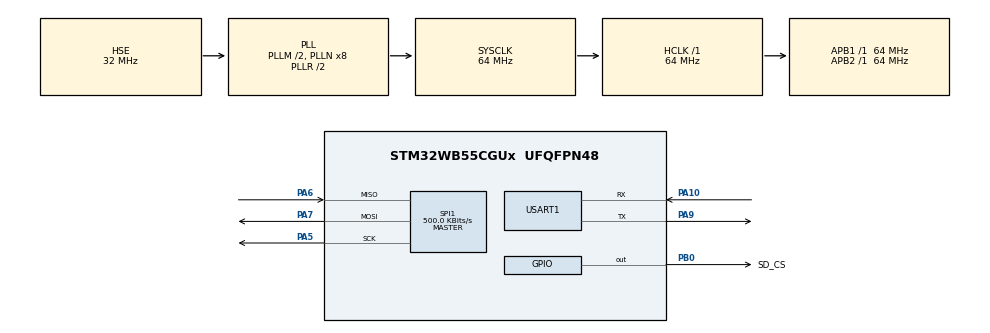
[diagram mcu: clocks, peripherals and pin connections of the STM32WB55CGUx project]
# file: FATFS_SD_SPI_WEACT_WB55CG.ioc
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Mcu.Family=STM32WB
Mcu.Name=STM32WB55CGUx
Mcu.Package=UFQFPN48
NVIC.PriorityGroup=NVIC_PRIORITYGROUP_4
OSC_IN.Mode=HSE-External-Oscillator
OSC_IN.Signal=RCC_OSC_IN
OSC_OUT.Mode=HSE-External-Oscillator
OSC_OUT.Signal=RCC_OSC_OUT
PA10.Mode=Asynchronous
PA10.Signal=USART1_RX
PA5.Mode=Full_Duplex_Master
PA5.Signal=SPI1_SCK
PA6.Mode=Full_Duplex_Master
PA6.Signal=SPI1_MISO
PA7.Mode=Full_Duplex_Master
PA7.Signal=SPI1_MOSI
PA9.Mode=Asynchronous
PA9.Signal=USART1_TX
PB0.GPIO_Label=SD_CS
PB0.GPIO_Speed=GPIO_SPEED_FREQ_HIGH
PB0.PinState=GPIO_PIN_SET
PB0.Signal=GPIO_Output
ProjectManager.HeapSize=0x200
ProjectManager.StackSize=0x400
ProjectManager.TargetToolchain=STM32CubeIDE
RCC.ADCFreq_Value=64000000
RCC.AHB2CLKDivider=RCC_SYSCLK_DIV2
RCC.AHBFreq_Value=64000000
RCC.APB1Freq_Value=64000000
RCC.APB1TimFreq_Value=64000000
RCC.APB2Freq_Value=64000000
RCC.APB2TimFreq_Value=64000000
RCC.APB3Freq_Value=16000000
RCC.Cortex2_Div=SYSTICK_CLKSOURCE_HCLK_DIV8
RCC.CortexFreq_Value=64000000
RCC.HCLKFreq_Value=64000000
RCC.HSE_VALUE=32000000
RCC.HSI48_VALUE=48000000
RCC.HSI_VALUE=16000000
RCC.LSE_VALUE=32768
RCC.PLLM=RCC_PLLM_DIV2
RCC.PLLSourceVirtual=RCC_PLLSOURCE_HSE
RCC.SYSCLKFreq_VALUE=64000000
RCC.SYSCLKSource=RCC_SYSCLKSOURCE_PLLCLK
RCC.USBFreq_Value=64000000
RCC.VCOOutputFreq_Value=128000000
SPI1.BaudRatePrescaler=SPI_BAUDRATEPRESCALER_128
SPI1.CalculateBaudRate=500.0 KBits/s
SPI1.DataSize=SPI_DATASIZE_8BIT
SPI1.Direction=SPI_DIRECTION_2LINES
SPI1.Mode=SPI_MODE_MASTER
SPI1.VirtualType=VM_MASTER
USART1.VirtualMode-Asynchronous=VM_ASYNC
VP_FATFS_VS_Generic.Mode=User_defined
VP_MEMORYMAP_VS_MEMORYMAP.Mode=CurAppReg
board=custom

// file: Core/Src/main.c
/* USER CODE BEGIN Header */
/**
  ******************************************************************************
  * @file           : main.c
  * @brief          : Main program body
  ******************************************************************************
  * @attention
  *
  * Copyright (c) 2026 STMicroelectronics.
  * All rights reserved.
  *
  * This software is licensed under terms that can be found in the LICENSE file
  * in the root directory of this software component.
  * If no LICENSE file comes with this software, it is provided AS-IS.
  *
  ******************************************************************************
  */
/* USER CODE END Header */
#include "main.h"
#include "app_fatfs.h"

/* USER CODE BEGIN Includes */
#include <string.h>
#include <stdio.h>
#include "sd_spi.h"
/* USER CODE END Includes */

SPI_HandleTypeDef hspi1;

UART_HandleTypeDef huart1;

void SystemClock_Config(void);
void PeriphCommonClock_Config(void);
static void MX_GPIO_Init(void);
static void MX_SPI1_Init(void);
static void MX_USART1_UART_Init(void);

int main(void)
{

  /* MCU Configuration--------------------------------------------------------*/

  /* Reset of all peripherals, Initializes the Flash interface and the Systick. */
  HAL_Init();

  /* Configure the system clock */
  SystemClock_Config();

  /* Configure the peripherals common clocks */
  PeriphCommonClock_Config();

  /* Initialize all configured peripherals */
  MX_GPIO_Init();
  MX_SPI1_Init();
  if (MX_FATFS_Init() != APP_OK) {
    Error_Handler();
  }
  MX_USART1_UART_Init();
  /* USER CODE BEGIN 2 */

  printf("==== READ/WRITE DEMO ====\r\n");
  printf("SD + SPI + FATFS\r\n");

  SD_FATFS_ReadWriteDemo();

  printf("==== DONE ====\r\n");

  /* USER CODE END 2 */

  /* Infinite loop */
  while (1)
  {

  }
}

void SystemClock_Config(void)
{
  RCC_OscInitTypeDef RCC_OscInitStruct = {0};
  RCC_ClkInitTypeDef RCC_ClkInitStruct = {0};

  /** Configure the main internal regulator output voltage
  */
  __HAL_PWR_VOLTAGESCALING_CONFIG(PWR_REGULATOR_VOLTAGE_SCALE1);

  /** Initializes the RCC Oscillators according to the specified parameters
  * in the RCC_OscInitTypeDef structure.
  */
  RCC_OscInitStruct.OscillatorType = RCC_OSCILLATORTYPE_HSI|RCC_OSCILLATORTYPE_HSE;
  RCC_OscInitStruct.HSEState = RCC_HSE_ON;
  RCC_OscInitStruct.HSIState = RCC_HSI_ON;
  RCC_OscInitStruct.HSICalibrationValue = RCC_HSICALIBRATION_DEFAULT;
  RCC_OscInitStruct.PLL.PLLState = RCC_PLL_ON;
  RCC_OscInitStruct.PLL.PLLSource = RCC_PLLSOURCE_HSE;
  RCC_OscInitStruct.PLL.PLLM = RCC_PLLM_DIV2;
  RCC_OscInitStruct.PLL.PLLN = 8;
  RCC_OscInitStruct.PLL.PLLP = RCC_PLLP_DIV2;
  RCC_OscInitStruct.PLL.PLLR = RCC_PLLR_DIV2;
  RCC_OscInitStruct.PLL.PLLQ = RCC_PLLQ_DIV2;
  if (HAL_RCC_OscConfig(&RCC_OscInitStruct) != HAL_OK)
  {
    Error_Handler();
  }

  /** Configure the SYSCLKSource, HCLK, PCLK1 and PCLK2 clocks dividers
  */
  RCC_ClkInitStruct.ClockType = RCC_CLOCKTYPE_HCLK4|RCC_CLOCKTYPE_HCLK2
                              |RCC_CLOCKTYPE_HCLK|RCC_CLOCKTYPE_SYSCLK
                              |RCC_CLOCKTYPE_PCLK1|RCC_CLOCKTYPE_PCLK2;
  RCC_ClkInitStruct.SYSCLKSource = RCC_SYSCLKSOURCE_PLLCLK;
  RCC_ClkInitStruct.AHBCLKDivider = RCC_SYSCLK_DIV1;
  RCC_ClkInitStruct.APB1CLKDivider = RCC_HCLK_DIV1;
  RCC_ClkInitStruct.APB2CLKDivider = RCC_HCLK_DIV1;
  RCC_ClkInitStruct.AHBCLK2Divider = RCC_SYSCLK_DIV2;
  RCC_ClkInitStruct.AHBCLK4Divider = RCC_SYSCLK_DIV1;

  if (HAL_RCC_ClockConfig(&RCC_ClkInitStruct, FLASH_LATENCY_3) != HAL_OK)
  {
    Error_Handler();
  }
}

void PeriphCommonClock_Config(void)
{
  RCC_PeriphCLKInitTypeDef PeriphClkInitStruct = {0};

  /** Initializes the peripherals clock
  */
  PeriphClkInitStruct.PeriphClockSelection = RCC_PERIPHCLK_SMPS;
  PeriphClkInitStruct.SmpsClockSelection = RCC_SMPSCLKSOURCE_HSI;
  PeriphClkInitStruct.SmpsDivSelection = RCC_SMPSCLKDIV_RANGE1;

  if (HAL_RCCEx_PeriphCLKConfig(&PeriphClkInitStruct) != HAL_OK)
  {
    Error_Handler();
  }
}

static void MX_SPI1_Init(void)
{

  /* SPI1 parameter configuration*/
  hspi1.Instance = SPI1;
  hspi1.Init.Mode = SPI_MODE_MASTER;
  hspi1.Init.Direction = SPI_DIRECTION_2LINES;
  hspi1.Init.DataSize = SPI_DATASIZE_8BIT;
  hspi1.Init.CLKPolarity = SPI_POLARITY_LOW;
  hspi1.Init.CLKPhase = SPI_PHASE_1EDGE;
  hspi1.Init.NSS = SPI_NSS_SOFT;
  hspi1.Init.BaudRatePrescaler = SPI_BAUDRATEPRESCALER_128;
  hspi1.Init.FirstBit = SPI_FIRSTBIT_MSB;
  hspi1.Init.TIMode = SPI_TIMODE_DISABLE;
  hspi1.Init.CRCCalculation = SPI_CRCCALCULATION_DISABLE;
  hspi1.Init.CRCPolynomial = 7;
  hspi1.Init.CRCLength = SPI_CRC_LENGTH_DATASIZE;
  hspi1.Init.NSSPMode = SPI_NSS_PULSE_ENABLE;
  if (HAL_SPI_Init(&hspi1) != HAL_OK)
  {
    Error_Handler();
  }

}

static void MX_USART1_UART_Init(void)
{

  huart1.Instance = USART1;
  huart1.Init.BaudRate = 115200;
  huart1.Init.WordLength = UART_WORDLENGTH_8B;
  huart1.Init.StopBits = UART_STOPBITS_1;
  huart1.Init.Parity = UART_PARITY_NONE;
  huart1.Init.Mode = UART_MODE_TX_RX;
  huart1.Init.HwFlowCtl = UART_HWCONTROL_NONE;
  huart1.Init.OverSampling = UART_OVERSAMPLING_16;
  huart1.Init.OneBitSampling = UART_ONE_BIT_SAMPLE_DISABLE;
  huart1.Init.ClockPrescaler = UART_PRESCALER_DIV1;
  huart1.AdvancedInit.AdvFeatureInit = UART_ADVFEATURE_NO_INIT;
  if (HAL_UART_Init(&huart1) != HAL_OK)
  {
    Error_Handler();
  }
  if (HAL_UARTEx_SetTxFifoThreshold(&huart1, UART_TXFIFO_THRESHOLD_1_8) != HAL_OK)
  {
    Error_Handler();
  }
  if (HAL_UARTEx_SetRxFifoThreshold(&huart1, UART_RXFIFO_THRESHOLD_1_8) != HAL_OK)
  {
    Error_Handler();
  }
  if (HAL_UARTEx_DisableFifoMode(&huart1) != HAL_OK)
  {
    Error_Handler();
  }

}

static void MX_GPIO_Init(void)
{
  GPIO_InitTypeDef GPIO_InitStruct = {0};

  /* GPIO Ports Clock Enable */
  __HAL_RCC_GPIOA_CLK_ENABLE();
  __HAL_RCC_GPIOB_CLK_ENABLE();

  /*Configure GPIO pin Output Level */
  HAL_GPIO_WritePin(SD_CS_GPIO_Port, SD_CS_Pin, GPIO_PIN_SET);

  /*Configure GPIO pin : SD_CS_Pin */
  GPIO_InitStruct.Pin = SD_CS_Pin;
  GPIO_InitStruct.Mode = GPIO_MODE_OUTPUT_PP;
  GPIO_InitStruct.Pull = GPIO_NOPULL;
  GPIO_InitStruct.Speed = GPIO_SPEED_FREQ_HIGH;
  HAL_GPIO_Init(SD_CS_GPIO_Port, &GPIO_InitStruct);

}

void Error_Handler(void)
{
  __disable_irq();
  while (1)
  {
  }
}
